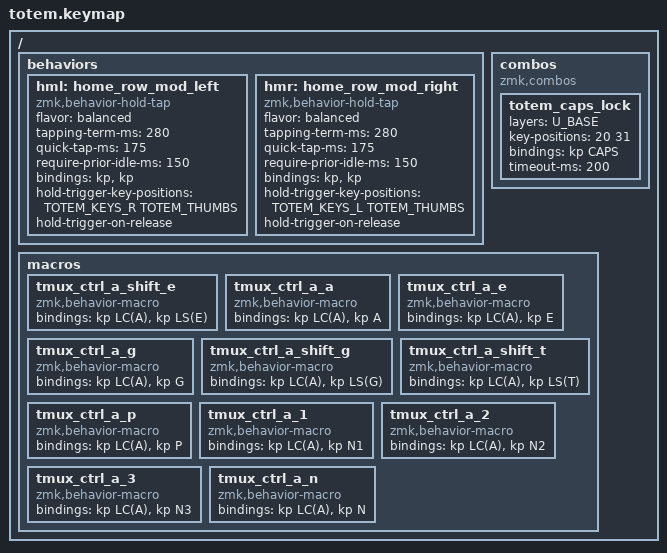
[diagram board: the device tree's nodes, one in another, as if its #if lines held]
// Copyright 2022 Manna Harbour
// https://github.com/manna-harbour/miryoku

#include "../miryoku/custom_config.h"
#include "../miryoku/mapping/38/totem.h"

#if defined(MIRYOKU_ALPHAS_QWERTY)
#define MIRYOKU_LAYER_LIST \
MIRYOKU_X(BASE,   "Base") \
MIRYOKU_X(EXTRA,  "Extra") \
MIRYOKU_X(TAP,    "Tap") \
MIRYOKU_X(BUTTON, "Button") \
MIRYOKU_X(NAV,    "Nav") \
MIRYOKU_X(MOUSE,  "Mouse") \
MIRYOKU_X(MEDIA,  "Media") \
MIRYOKU_X(NUM,    "Num") \
MIRYOKU_X(SYM,    "Sym") \
MIRYOKU_X(FUN,    "Fun") \
MIRYOKU_X(TMUX,   "Tmux")

#define U_BASE   0
#define U_EXTRA  1
#define U_TAP    2
#define U_BUTTON 3
#define U_NAV    4
#define U_MOUSE  5
#define U_MEDIA  6
#define U_NUM    7
#define U_SYM    8
#define U_FUN    9
#define U_TMUX   10

#define TOTEM_KEYS_L 0 1 2 3 4 10 11 12 13 14 20 21 22 23 24 25
#define TOTEM_KEYS_R 5 6 7 8 9 15 16 17 18 19 26 27 28 29 30 31
#define TOTEM_THUMBS 32 33 34 35 36 37

/ {
  behaviors {
    hml: home_row_mod_left {
      compatible = "zmk,behavior-hold-tap";
      #binding-cells = <2>;
      flavor = "balanced";
      tapping-term-ms = <280>;
      quick-tap-ms = <175>;
      require-prior-idle-ms = <150>;
      bindings = <&kp>, <&kp>;
      hold-trigger-key-positions = <TOTEM_KEYS_R TOTEM_THUMBS>;
      hold-trigger-on-release;
    };

    hmr: home_row_mod_right {
      compatible = "zmk,behavior-hold-tap";
      #binding-cells = <2>;
      flavor = "balanced";
      tapping-term-ms = <280>;
      quick-tap-ms = <175>;
      require-prior-idle-ms = <150>;
      bindings = <&kp>, <&kp>;
      hold-trigger-key-positions = <TOTEM_KEYS_L TOTEM_THUMBS>;
      hold-trigger-on-release;
    };
  };
};

#define MIRYOKU_LAYER_BASE \
&kp Q,             &kp W,             &kp E,             &kp R,             &kp T,             &kp Y,             &kp U,             &kp I,             &kp O,             &kp P,             \
&hml LGUI A,       &hml LALT S,       &hml LCTRL D,      &hml LSHFT F,      &kp G,             &kp H,             &hmr LSHFT J,      &hmr LCTRL K,      &hmr LALT L,       &hmr LGUI SQT,     \
U_LT(U_BUTTON, Z), U_MT(RALT, X),     &kp C,             &kp V,             &kp B,             &kp N,             &kp M,             &kp COMMA,         U_MT(RALT, DOT),   U_LT(U_BUTTON, SLASH),\
&kp LSHFT,         U_NP,              U_LT(U_TMUX, ESC), U_LT(U_NAV, BSPC), U_LT(U_MOUSE, TAB),U_LT(U_SYM, RET),  U_LT(U_NUM, SPACE),U_LT(U_FUN, DEL),  U_NP,              &kp RSHFT

#define MIRYOKU_LAYER_TMUX \
U_BOOT,            &u_to_U_TAP,       &u_to_U_EXTRA,     &u_to_U_BASE,      U_NA,              &tmux_ctrl_a_shift_e,&tmux_ctrl_a_a,    &tmux_ctrl_a_e,    &tmux_ctrl_a_g,    &tmux_ctrl_a_shift_g,\
&kp LGUI,          &kp LALT,          &kp LCTRL,         &kp LSHFT,         U_NA,              &tmux_ctrl_a_shift_t,&kp LC(LEFT),      &kp LC(DOWN),      &kp LC(UP),        &kp LC(RIGHT),     \
U_NA,              &kp RALT,          &u_to_U_NUM,       &u_to_U_TMUX,      U_NA,              &tmux_ctrl_a_p,    &tmux_ctrl_a_1,    &tmux_ctrl_a_2,    &tmux_ctrl_a_3,    &tmux_ctrl_a_n,    \
U_NP,              U_NP,              U_NA,              U_NA,              U_NA,              &kp RET,           &kp BSPC,          &kp DEL,           U_NP,              U_NP

#define MIRYOKU_LAYERMAPPING_TMUX MIRYOKU_MAPPING

#define MIRYOKU_LAYER_FUN \
&kp F12,           &kp F7,            &kp F8,            &kp F9,            &kp PSCRN,         U_RGB_TOG,         &kp C_PREV,        &kp C_VOL_UP,      &kp C_NEXT,        U_RGB_BRI,         \
&kp F11,           &kp F4,            &kp F5,            &kp F6,            &kp SLCK,          U_EP_TOG,          &kp C_MUTE,        &kp C_VOL_DN,      &kp C_PP,          U_RGB_EFF,         \
&kp F10,           &kp F1,            &kp F2,            &kp F3,            &kp PAUSE_BREAK,   &kp C_STOP,        &kp C_PREV,        &kp C_PP,          &kp C_NEXT,        &kp C_MUTE,        \
U_NP,              U_NP,              &kp K_APP,         &kp SPACE,         &kp TAB,           U_NA,              U_NA,              U_NA,              U_NP,              U_NP
#endif

#include "../miryoku/miryoku.dtsi"

#if defined(MIRYOKU_ALPHAS_QWERTY)
/ {
  combos {
    compatible = "zmk,combos";

    totem_caps_lock {
      layers = <U_BASE>;
      key-positions = <20 31>;
      bindings = <&kp CAPS>;
      timeout-ms = <200>;
    };
  };

  macros {
    tmux_ctrl_a_shift_e: tmux_ctrl_a_shift_e {
      compatible = "zmk,behavior-macro";
      #binding-cells = <0>;
      bindings = <&kp LC(A) &kp LS(E)>;
    };
    tmux_ctrl_a_a: tmux_ctrl_a_a {
      compatible = "zmk,behavior-macro";
      #binding-cells = <0>;
      bindings = <&kp LC(A) &kp A>;
    };
    tmux_ctrl_a_e: tmux_ctrl_a_e {
      compatible = "zmk,behavior-macro";
      #binding-cells = <0>;
      bindings = <&kp LC(A) &kp E>;
    };
    tmux_ctrl_a_g: tmux_ctrl_a_g {
      compatible = "zmk,behavior-macro";
      #binding-cells = <0>;
      bindings = <&kp LC(A) &kp G>;
    };
    tmux_ctrl_a_shift_g: tmux_ctrl_a_shift_g {
      compatible = "zmk,behavior-macro";
      #binding-cells = <0>;
      bindings = <&kp LC(A) &kp LS(G)>;
    };
    tmux_ctrl_a_shift_t: tmux_ctrl_a_shift_t {
      compatible = "zmk,behavior-macro";
      #binding-cells = <0>;
      bindings = <&kp LC(A) &kp LS(T)>;
    };
    tmux_ctrl_a_p: tmux_ctrl_a_p {
      compatible = "zmk,behavior-macro";
      #binding-cells = <0>;
      bindings = <&kp LC(A) &kp P>;
    };
    tmux_ctrl_a_1: tmux_ctrl_a_1 {
      compatible = "zmk,behavior-macro";
      #binding-cells = <0>;
      bindings = <&kp LC(A) &kp N1>;
    };
    tmux_ctrl_a_2: tmux_ctrl_a_2 {
      compatible = "zmk,behavior-macro";
      #binding-cells = <0>;
      bindings = <&kp LC(A) &kp N2>;
    };
    tmux_ctrl_a_3: tmux_ctrl_a_3 {
      compatible = "zmk,behavior-macro";
      #binding-cells = <0>;
      bindings = <&kp LC(A) &kp N3>;
    };
    tmux_ctrl_a_n: tmux_ctrl_a_n {
      compatible = "zmk,behavior-macro";
      #binding-cells = <0>;
      bindings = <&kp LC(A) &kp N>;
    };
  };
};
#endif
